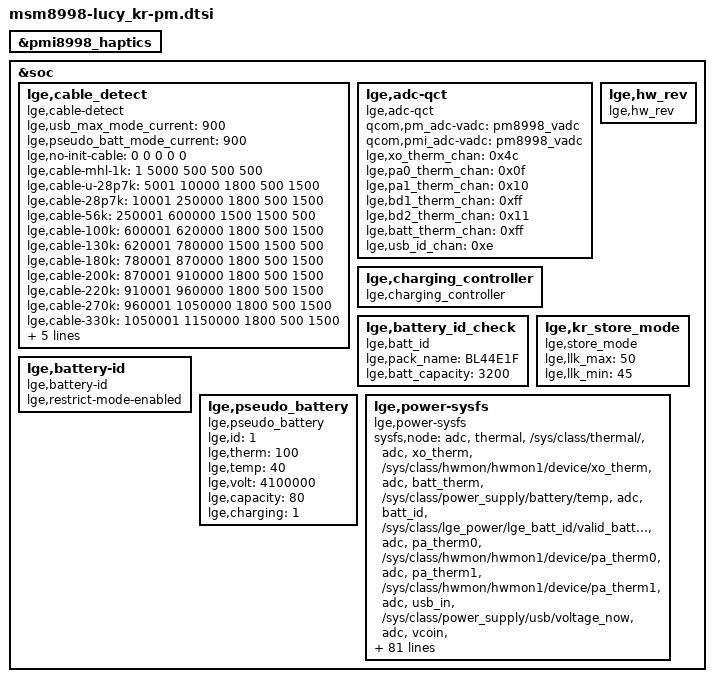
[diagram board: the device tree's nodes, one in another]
/* Copyright (c) 2016, The Linux Foundation. All rights reserved.
 *
 * This program is free software; you can redistribute it and/or modify
 * it under the terms of the GNU General Public License version 2 and
 * only version 2 as published by the Free Software Foundation.
 *
 * This program is distributed in the hope that it will be useful,
 * but WITHOUT ANY WARRANTY; without even the implied warranty of
 * MERCHANTABILITY or FITNESS FOR A PARTICULAR PURPOSE.  See the
 * GNU General Public License for more details.
 */

#include "../../msm8998-lucy/msm8998-lucy-common/msm8998-lucy-common-pm.dtsi"

&pmi8998_haptics {
	status = "okay";
};

&soc {
	lge,cable_detect {
		status = "ok";
		compatible = "lge,cable-detect";

		lge,usb_max_mode_current = <900>;
		lge,pseudo_batt_mode_current = <900>;

		lge,no-init-cable 	= <      0       0    0    0    0>;
		lge,cable-mhl-1k 	= <      1    5000  500  500  500>;
		lge,cable-u-28p7k 	= <   5001   10000 1800  500 1500>;
		lge,cable-28p7k 	= <  10001  250000 1800  500 1500>;
		lge,cable-56k 		= < 250001  600000 1500 1500  500>;
		lge,cable-100k 		= < 600001  620000 1800  500 1500>;
		lge,cable-130k 		= < 620001  780000 1500 1500  500>;
		lge,cable-180k 		= < 780001  870000 1800  500 1500>;
		lge,cable-200k 		= < 870001  910000 1800  500 1500>;
		lge,cable-220k 		= < 910001  960000 1800  500 1500>;
		lge,cable-270k 		= < 960001 1050000 1800  500 1500>;
		lge,cable-330k 		= <1050001 1150000 1800  500 1500>;
		lge,cable-620k 		= <1150001 1380000 1800  500 1500>;
		lge,cable-910k 		= <1380001 1630000 1500 1500  500>;
		lge,cable-none 		= <1630001 1900000 1800  500 1500>;

		lge,fastchg_usb_icl = <3000>;
		lge,fastchg_fcc_icl = <3000>;
	};

	lge,adc-qct {
		compatible = "lge,adc-qct";
		qcom,pm_adc-vadc = <&pm8998_vadc>;
		qcom,pmi_adc-vadc = <&pm8998_vadc>;
		lge,xo_therm_chan = <0x4c>;
		lge,pa0_therm_chan = <0x0f>;
		lge,pa1_therm_chan = <0x10>;
		lge,bd1_therm_chan = <0xff>;
		lge,bd2_therm_chan = <0x11>;
		lge,batt_therm_chan = <0xff>;
		lge,usb_id_chan = <0xe>;
	};

	lge,charging_controller {
		compatible = "lge,charging_controller";
	};

	lge,battery_id_check {
		compatible = "lge,batt_id";
		lge,pack_name = "BL44E1F";
		lge,batt_capacity = "3200";
	};
	lge,hw_rev {
		compatible = "lge,hw_rev";
	};

	lge,kr_store_mode {
		compatible = "lge,store_mode";
		lge,llk_max = <50>;
		lge,llk_min = <45>;
	};
	lge,battery-id {
		compatible = "lge,battery-id";
		lge,restrict-mode-enabled;
	};

	lge,pseudo_battery {
		compatible = "lge,pseudo_battery";
		lge,id = <1>;
		lge,therm = <100>;
		lge,temp = <40>;
		lge,volt = <4100000>;
		lge,capacity = <80>;
		lge,charging = <1>;
	};

	lge,power-sysfs {
		status = "ok";
		compatible = "lge,power-sysfs";

		sysfs,node =
			/* group , user_node, kernel node */
			/* ADC/MPP */
			"adc", "thermal", "/sys/class/thermal/",
			"adc", "xo_therm", "/sys/class/hwmon/hwmon1/device/xo_therm",
			"adc", "batt_therm", "/sys/class/power_supply/battery/temp",
			"adc", "batt_id", "/sys/class/lge_power/lge_batt_id/valid_batt_id",
			"adc", "pa_therm0", "/sys/class/hwmon/hwmon1/device/pa_therm0",
			"adc", "pa_therm1", "/sys/class/hwmon/hwmon1/device/pa_therm1",
			"adc", "usb_in", "/sys/class/power_supply/usb/voltage_now",
			"adc", "vcoin", "/sys/class/hwmon/hwmon1/device/vcoin",
			"adc", "vph_pwr", "/sys/class/hwmon/hwmon1/device/vph_pwr",
			"adc", "usb_id", "/sys/class/hwmon/hwmon1/device/usb_id_lv",
			"adc", "vts", "/sys/class/thermal/thermal_zone34/temp",
			"adc", "pmic", "/sys/class/thermal/thermal_zone1/temp",
			/* Battery */
			"battery", "capacity", "/sys/class/power_supply/battery/capacity",
			"battery", "health", "/sys/class/power_supply/battery/health",
			"battery", "present", "/sys/class/power_supply/battery/present",
			"battery", "pseudo_batt", "/sys/class/lge_power/pseudo_battery/pseudo_batt",
			"battery", "status", "/sys/class/power_supply/battery/status",
			"battery", "temp", "/sys/class/power_supply/battery/temp",
			"battery", "valid_batt_id", "/sys/class/lge_power/lge_batt_id/valid_batt_id",
			"battery", "voltage_now", "/sys/class/power_supply/battery/voltage_now",
			/* Charger */
			"charger", "ac_online", "NULL",
			"charger", "usb_online", "/sys/class/power_supply/usb/online",
			"charger", "present", "/sys/class/power_supply/usb/present",
			"charger", "wlc_online", "NULL",
			"charger", "type", "/sys/class/power_supply/usb/type",
			"charger", "time_out", "/sys/class/power_supply/battery/safety_timer_enabled",
			"charger", "charging_enabled", "/sys/class/power_supply/battery/charging_enabled",
			"charger", "ibat_current", "/sys/class/power_supply/battery/current_now",
			"charger", "ichg_current", "/sys/class/power_supply/usb/current_max",
			"charger", "iusb_control", "NULL",
			"charger", "thermal_mitigation", "/sys/class/power_supply/battery/system_temp_level",
			"charger", "wlc_thermal_mitigation", "NULL",
			"charger", "usb_parallel_chg_status", "NULL",
			"charger", "usb_parallel_charging_enabled", "NULL",
			"charger", "quick_charging_state", "/sys/module/lge_power_class_charging_controller/parameters/quick_charging_state",
			"charger", "ibat_max_current", "/sys/class/power_supply/battery/constant_charge_current_max",
			/* LCD Backlight */
			"lcd", "brightness", "/sys/class/leds/lcd-backlight/brightness",
			"lcd", "max_brightness", "/sys/class/leds/lcd-backlight/max_brightness",
			"lcd_ex", "brightness", "NULL",
			"lcd_ex", "max_brightness", "NULL",
			/* KEY LED */
			"key_led", "red_brightness", "/sys/class/leds/red/brightness",
			"key_led", "green_brightness", "/sys/class/leds/green/brightness",
			"key_led", "blue_brightness", "/sys/class/leds/blue/brightness",
			/* CPU */
			"cpu", "cpu_idle_modes", "/sys/module/lpm_levels/system/",
			/* GPU */
			"gpu", "busy", "/sys/class/kgsl/kgsl-3d0/gpubusy",
			/* PLATFORM */
			"platform", "speed_bin", "NULL",
			"platform", "pvs_bin", "NULL",
			"platform", "power_state", "/sys/power/autosleep",
			"platform", "poweron_alarm", "/sys/module/qpnp_rtc/parameters/poweron_alarm",
			"platform", "pcb_rev", "/sys/class/hwmon/hwmon1/device/pcb_rev",
			/* testmode */
			"testmode", "charge", "/sys/class/power_supply/battery/battery_charging_enabled",
			"testmode", "chcomp", "/sys/class/power_supply/battery/device/at_chcomp",
			"testmode", "chgmodeoff", "/sys/class/power_supply/battery/input_suspend",
			"testmode", "fuelrst", "NULL",
			"testmode", "rtc_time", "/dev/rtc0",
			"testmode", "pmrst", "NULL",
			"testmode", "battexit", "/sys/class/power_supply/battery/present",
			"testmode", "hardreset_mode", "NULL";
	};
};
